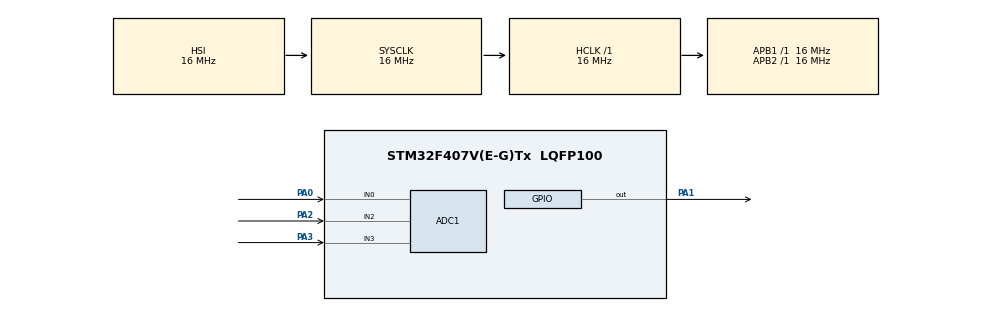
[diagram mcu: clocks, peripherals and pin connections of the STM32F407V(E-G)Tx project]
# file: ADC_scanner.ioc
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ADC1.Channel-0\#ChannelRegularConversion=ADC_CHANNEL_0
ADC1.Channel-1\#ChannelRegularConversion=ADC_CHANNEL_2
ADC1.Channel-2\#ChannelRegularConversion=ADC_CHANNEL_3
ADC1.ContinuousConvMode=ENABLE
ADC1.DMAContinuousRequests=ENABLE
ADC1.NbrOfConversion=3
ADC1.NbrOfConversionFlag=1
ADC1.Rank-0\#ChannelRegularConversion=1
ADC1.Rank-1\#ChannelRegularConversion=2
ADC1.Rank-2\#ChannelRegularConversion=3
ADC1.SamplingTime-0\#ChannelRegularConversion=ADC_SAMPLETIME_144CYCLES
ADC1.SamplingTime-1\#ChannelRegularConversion=ADC_SAMPLETIME_144CYCLES
ADC1.SamplingTime-2\#ChannelRegularConversion=ADC_SAMPLETIME_144CYCLES
ADC1.ScanConvMode=ENABLE
ADC1.master=1
Dma.ADC1.0.Direction=DMA_PERIPH_TO_MEMORY
Dma.ADC1.0.FIFOMode=DMA_FIFOMODE_DISABLE
Dma.ADC1.0.Instance=DMA2_Stream0
Dma.ADC1.0.MemDataAlignment=DMA_MDATAALIGN_HALFWORD
Dma.ADC1.0.MemInc=DMA_MINC_ENABLE
Dma.ADC1.0.Mode=DMA_CIRCULAR
Dma.ADC1.0.PeriphDataAlignment=DMA_PDATAALIGN_HALFWORD
Dma.ADC1.0.PeriphInc=DMA_PINC_DISABLE
Dma.ADC1.0.Priority=DMA_PRIORITY_LOW
Dma.Request0=ADC1
Mcu.Family=STM32F4
Mcu.Name=STM32F407V(E-G)Tx
Mcu.Package=LQFP100
NVIC.DMA2_Stream0_IRQn=true\:0\:0\:false\:false\:true\:false\:true
NVIC.PriorityGroup=NVIC_PRIORITYGROUP_4
PA0-WKUP.Signal=ADCx_IN0
PA1.Signal=GPIO_Output
PA2.Signal=ADCx_IN2
PA3.Signal=ADCx_IN3
ProjectManager.HeapSize=0x200
ProjectManager.StackSize=0x400
ProjectManager.TargetToolchain=MDK-ARM V5.27
RCC.AHBFreq_Value=16000000
RCC.APB1Freq_Value=16000000
RCC.APB2Freq_Value=16000000
RCC.CortexFreq_Value=16000000
RCC.HSE_VALUE=25000000
RCC.HSI_VALUE=16000000
RCC.LSE_VALUE=32768
RCC.SYSCLKFreq_VALUE=16000000
RCC.VCOOutputFreq_Value=192000000
SH.ADCx_IN0.0=ADC1_IN0,IN0
SH.ADCx_IN2.0=ADC1_IN2,IN2
SH.ADCx_IN3.0=ADC1_IN3,IN3
board=custom

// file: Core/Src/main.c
/* USER CODE BEGIN Header */
/**
  ******************************************************************************
  * @file           : main.c
  * @brief          : Main program body
  ******************************************************************************
  * @attention
  *
  * <h2><center>&copy; Copyright (c) 2021 STMicroelectronics.
  * All rights reserved.</center></h2>
  *
  * This software component is licensed by ST under BSD 3-Clause license,
  * the "License"; You may not use this file except in compliance with the
  * License. You may obtain a copy of the License at:
  *                        opensource.org/licenses/BSD-3-Clause
  *
  ******************************************************************************
  */
/* USER CODE END Header */
#include "main.h"
#include "adc.h"
#include "dma.h"
#include "gpio.h"

/* USER CODE BEGIN PV */
uint16_t adcArr[3];
/* USER CODE END PV */

void SystemClock_Config(void);

int main(void)
{

  /* MCU Configuration--------------------------------------------------------*/

  /* Reset of all peripherals, Initializes the Flash interface and the Systick. */
  HAL_Init();

  /* Configure the system clock */
  SystemClock_Config();

  /* Initialize all configured peripherals */
  MX_GPIO_Init();
  MX_DMA_Init();
  MX_ADC1_Init();
  /* USER CODE BEGIN 2 */
	HAL_ADC_Start_DMA(&hadc1,(uint32_t*)adcArr,3);
  /* USER CODE END 2 */

  /* Infinite loop */
  while (1)
  {

  }
}

void SystemClock_Config(void)
{
  RCC_OscInitTypeDef RCC_OscInitStruct = {0};
  RCC_ClkInitTypeDef RCC_ClkInitStruct = {0};

  /** Configure the main internal regulator output voltage
  */
  __HAL_RCC_PWR_CLK_ENABLE();
  __HAL_PWR_VOLTAGESCALING_CONFIG(PWR_REGULATOR_VOLTAGE_SCALE1);
  /** Initializes the RCC Oscillators according to the specified parameters
  * in the RCC_OscInitTypeDef structure.
  */
  RCC_OscInitStruct.OscillatorType = RCC_OSCILLATORTYPE_HSI;
  RCC_OscInitStruct.HSIState = RCC_HSI_ON;
  RCC_OscInitStruct.HSICalibrationValue = RCC_HSICALIBRATION_DEFAULT;
  RCC_OscInitStruct.PLL.PLLState = RCC_PLL_NONE;
  if (HAL_RCC_OscConfig(&RCC_OscInitStruct) != HAL_OK)
  {
    Error_Handler();
  }
  /** Initializes the CPU, AHB and APB buses clocks
  */
  RCC_ClkInitStruct.ClockType = RCC_CLOCKTYPE_HCLK|RCC_CLOCKTYPE_SYSCLK
                              |RCC_CLOCKTYPE_PCLK1|RCC_CLOCKTYPE_PCLK2;
  RCC_ClkInitStruct.SYSCLKSource = RCC_SYSCLKSOURCE_HSI;
  RCC_ClkInitStruct.AHBCLKDivider = RCC_SYSCLK_DIV1;
  RCC_ClkInitStruct.APB1CLKDivider = RCC_HCLK_DIV1;
  RCC_ClkInitStruct.APB2CLKDivider = RCC_HCLK_DIV1;

  if (HAL_RCC_ClockConfig(&RCC_ClkInitStruct, FLASH_LATENCY_0) != HAL_OK)
  {
    Error_Handler();
  }
}

void Error_Handler(void)
{
  __disable_irq();
  while (1)
  {
  }
}

/************************ (C) COPYRIGHT STMicroelectronics *****END OF FILE****/
